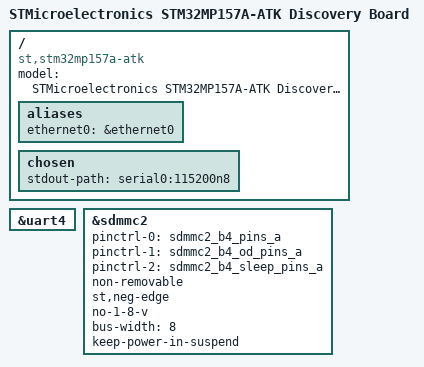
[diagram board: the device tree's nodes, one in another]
// SPDX-License-Identifier: (GPL-2.0+ OR BSD-3-Clause)
/*
 * Copyright (C) STMicroelectronics 2019 - All Rights Reserved
 * Author: Alexandre Torgue <alexandre.torgue@st.com> for STMicroelectronics.
 */

/dts-v1/;

#include "stm32mp157.dtsi"
#include "stm32mp15-pinctrl.dtsi"
#include "stm32mp15xxac-pinctrl.dtsi"
#include "stm32mp15xx-dkx.dtsi"

/ {
	model = "STMicroelectronics STM32MP157A-ATK Discovery Board";
	compatible = "st,stm32mp157a-atk", "st,stm32mp157";

	aliases {
		ethernet0 = &ethernet0;
	};

	chosen {
		stdout-path = "serial0:115200n8";
	};

};

&uart4{
	status = "okay";
};


&sdmmc2 {
	pinctrl-names = "default", "opendrain", "sleep";
	pinctrl-0 = <&sdmmc2_b4_pins_a>;
	pinctrl-1 = <&sdmmc2_b4_od_pins_a>;
	pinctrl-2 = <&sdmmc2_b4_sleep_pins_a>;
	non-removable;
	st,neg-edge;
    no-1-8-v;
	bus-width = <8>;
	keep-power-in-suspend;
	status = "okay";
};

